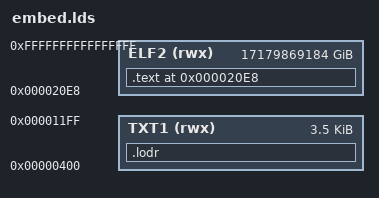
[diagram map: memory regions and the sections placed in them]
/* s390x Stand-Alone Linker Script      
   Generated by ipldpp.py - DO NOT EDIT */

OUTPUT_FORMAT(elf64-s390)
OUTPUT_ARCH(s390:64-bit)
TARGET(elf64-s390)
ENTRY(_start)

MEMORY
{
    TXT1 (rwx) : ORIGIN = 0x400, LENGTH = 0xE00
    ELF2 (rwx) : ORIGIN = 0x20E8, LENGTH = 0xFFFFFFFFFFFFDF18
}

PHDRS
{
    TEXT PT_LOAD    FLAGS ( 0x00000007 ) ;
    LODR PT_LOAD    FLAGS ( 0xF0000007 ) ;
}

SECTIONS
{
    .lodr   :    
    {
        *(.loader)
    } >TXT1  :LODR

    .text 0x20E8  :    
    {
        . = ALIGN(16) ;
        *(.text)
        . = ALIGN(16) ;
        *(.data)
        . = ALIGN(16) ;
        PROVIDE(_GOT_begin = .);
        *(.got)
        PROVIDE(_GOT_end = .);
        . = ALIGN(16) ;
        *(.shstrtab)
        . = ALIGN(16) ;
        *(.symtab)
        . = ALIGN(16) ;
        *(.strtab)
        . = ALIGN(16) ;
        *(.rela.text)
        . = ALIGN(16) ;
        *(.bss)
    } >ELF2  :TEXT

    /DISCARD/   :    
    {
        *(.rela.loader)
    }   

}

